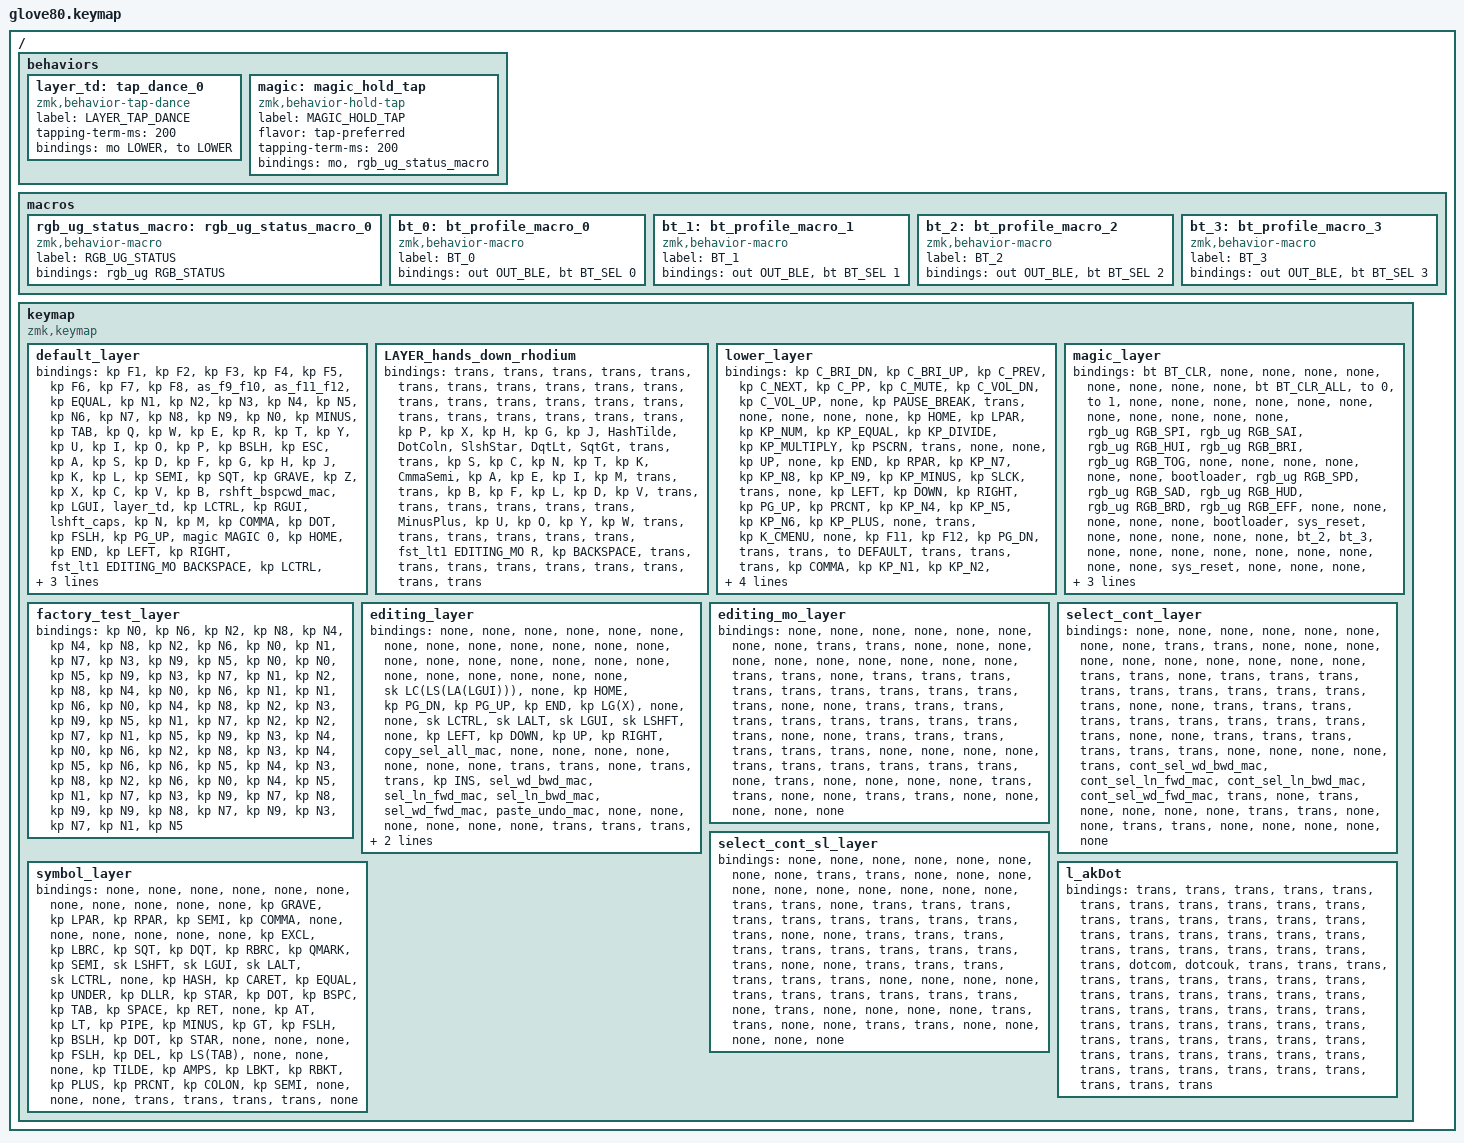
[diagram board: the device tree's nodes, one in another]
/*
 * Copyright (c) 2020 The ZMK Contributors
 *
 * SPDX-License-Identifier: MIT
 */

#include <behaviors.dtsi>
#include <dt-bindings/zmk/keys.h>
#include <dt-bindings/zmk/bt.h>
#include <dt-bindings/zmk/ext_power.h>
#include <dt-bindings/zmk/outputs.h>
#include <dt-bindings/zmk/rgb.h>

// layers
#define DEFAULT 0
#define RHODIUM 1
#define LOWER 2
#define MAGIC 3
#define FACTORY_TEST 4
#define EDITING 5
#define EDITING_MO 6
#define SELECT_CONT 7
#define SELECT_CONT_SL 8
#define SYMBOL 9
#define l_akDot 10

#define BASE_LAYERS DEFAULT
#define layers_hands_down RHODIUM DEFAULT

#include "base.keymap"
#include "keydefinitions.keymap"
#include "handsdown.keymap"

/ {
    behaviors {
        // For the "layer" key, it'd nice to be able to use it as either a shift or a toggle.
        // Configure it as a tap dance, so the first tap (or hold) is a &mo and the second tap is a &to
        layer_td: tap_dance_0 {
            compatible = "zmk,behavior-tap-dance";
            label = "LAYER_TAP_DANCE";
            #binding-cells = <0>;
            tapping-term-ms = <200>;
            bindings = <&mo LOWER>, <&to LOWER>;
        };

        magic: magic_hold_tap {
            compatible = "zmk,behavior-hold-tap";
            label = "MAGIC_HOLD_TAP";
            #binding-cells = <2>;
            flavor = "tap-preferred";
            tapping-term-ms = <200>;
            bindings = <&mo>, <&rgb_ug_status_macro>;
        };
    };

    macros {
        rgb_ug_status_macro: rgb_ug_status_macro_0 {
            label = "RGB_UG_STATUS";
            compatible = "zmk,behavior-macro";
            #binding-cells = <0>;
            bindings
                = <&rgb_ug RGB_STATUS>;
        };

        bt_0: bt_profile_macro_0 {
            label = "BT_0";
            compatible = "zmk,behavior-macro";
            #binding-cells = <0>;
            bindings
                = <&out OUT_BLE>,
                  <&bt BT_SEL 0>;
        };

        bt_1: bt_profile_macro_1 {
            label = "BT_1";
            compatible = "zmk,behavior-macro";
            #binding-cells = <0>;
            bindings
                = <&out OUT_BLE>,
                  <&bt BT_SEL 1>;
        };

        bt_2: bt_profile_macro_2 {
            label = "BT_2";
            compatible = "zmk,behavior-macro";
            #binding-cells = <0>;
            bindings
                = <&out OUT_BLE>,
                  <&bt BT_SEL 2>;
        };

        bt_3: bt_profile_macro_3 {
            label = "BT_3";
            compatible = "zmk,behavior-macro";
            #binding-cells = <0>;
            bindings
                = <&out OUT_BLE>,
                  <&bt BT_SEL 3>;
        };
    };

    keymap {
        compatible = "zmk,keymap";

        default_layer {
            // ---------------------------------------------------------------------------------------------------------------------------------
            // |  F1   |  F2 |  F3 |  F4  |  F5  |                                                               |  F6   |  F7   |  F8  |   F9  |  F10 |
            // |  =    |  1  |  2  |  3   |  4   |  5   |                                                 |  6   |   7   |   8   |  9   |   0   |   -  |
            // |  TAB  |  Q  |  W  |  E   |  R   |  T   |                                                 |  Y   |   U   |   I   |  O   |   P   |   \  |
            // |  ESC  |  A  |  S  |  D   |  F   |  G   |                                                 |  H   |   J   |   K   |  L   |   ;   |   '  |
            // |   `   |  Z  |  X  |  C   |  V   |  B   | LSHFT | LGUI | LOWER | | LCTRL  | RGUI | RSHFT |  N   |   M   |   ,   |  .   |   /   | PGUP |
            // | MAGIC | HOME| END | LEFT | RIGHT|      | BSPC  | LCTRL   | LALT  | | LALT  | RET   | SPACE |      |  UP   | DOWN  |  [   |   ]   | PGDN |

            bindings = <
            &kp F1         &kp F2   &kp F3      &kp F4      &kp F5                                                                                         &kp F6  &kp F7      &kp F8      &as_f9_f10      &as_f11_f12
            &kp EQUAL      &kp N1   &kp N2      &kp N3      &kp N4      &kp N5                                                                     &kp N6  &kp N7  &kp N8      &kp N9      &kp N0      &kp MINUS
            &kp TAB        &kp Q    &kp W       &kp E       &kp R       &kp T                                                                      &kp Y   &kp U   &kp I       &kp O       &kp P       &kp BSLH
            &kp ESC        &kp A    &kp S       &kp D       &kp F       &kp G                                                                      &kp H   &kp J   &kp K       &kp L       &kp SEMI    &kp SQT
            &kp GRAVE      &kp Z    &kp X       &kp C       &kp V       &kp B   &rshft_bspcwd_mac  &kp LGUI   &layer_td  &kp LCTRL  &kp RGUI &lshft_caps   &kp N   &kp M   &kp COMMA   &kp DOT     &kp FSLH    &kp PG_UP
            &magic MAGIC 0 &kp HOME &kp END     &kp LEFT    &kp RIGHT           &fst_lt1 EDITING_MO BACKSPACE    &kp LCTRL     &kp LALT   &kp LALT  &kp RET   &fst_lt SYMBOL SPACE           &kp UP  &kp DOWN    &kp LBKT    &kp RBKT    &kp PG_DN
            >;
        };

        LAYER_hands_down_rhodium {
            bindings = <
    &trans    &trans      &trans      &trans        &trans                                                                                        &trans          &trans          &trans        &trans      &trans
    &trans    &trans      &trans      &trans        &trans          &trans                                                            &trans      &trans          &trans          &trans        &trans      &trans
    &trans    &kp P       &kp X       &kp H         &kp G           &kp J                                                             &HashTilde  &DotColn        &SlshStar       &DqtLt      &SqtGt    &trans
    &trans    &kp S       &kp C       &kp N         &kp T           &kp K                                                             &CmmaSemi   &kp A           &kp E           &kp I         &kp M       &trans
    &trans    &kp B       &kp F       &kp L         &kp D           &kp V     &trans    &trans    &trans  &trans   &trans   &trans    &MinusPlus  &kp U           &kp O           &kp Y         &kp W       &trans
    &trans    &trans      &trans      &trans        &trans                    &fst_lt1 EDITING_MO R     &kp BACKSPACE  &trans  &trans   &trans &trans             &trans          &trans          &trans        &trans      &trans
            >;
        };

        lower_layer {
            bindings = <
            &kp C_BRI_DN      &kp C_BRI_UP        &kp C_PREV      &kp C_NEXT      &kp C_PP                                                                                                           &kp C_MUTE   &kp C_VOL_DN &kp C_VOL_UP  &none           &kp PAUSE_BREAK
            &trans            &none               &none           &none           &none           &kp HOME                                                                              &kp LPAR     &kp KP_NUM   &kp KP_EQUAL &kp KP_DIVIDE &kp KP_MULTIPLY &kp PSCRN
            &trans            &none               &none           &kp UP          &none           &kp END                                                                               &kp RPAR     &kp KP_N7    &kp KP_N8    &kp KP_N9     &kp KP_MINUS    &kp SLCK
            &trans            &none               &kp LEFT        &kp DOWN        &kp RIGHT       &kp PG_UP                                                                             &kp PRCNT    &kp KP_N4    &kp KP_N5    &kp KP_N6     &kp KP_PLUS     &none
            &trans            &kp K_CMENU         &none           &kp F11         &kp F12         &kp PG_DN       &trans      &trans      &to DEFAULT &trans      &trans      &trans    &kp COMMA    &kp KP_N1    &kp KP_N2    &kp KP_N3     &kp KP_ENTER    &trans
            &trans            &kp CAPS            &kp INS         &kp F11         &kp F12                         &trans      &trans      &trans      &trans      &trans      &trans                 &kp KP_N0    &kp KP_N0    &kp KP_DOT    &kp KP_ENTER    &trans
            >;
        };

        magic_layer {
            bindings = <
            &bt BT_CLR        &none               &none           &none           &none                                                                                                           &none      &none      &none      &none      &bt BT_CLR_ALL
            &to 0             &to 1               &none           &none           &none           &none                                                                                &none      &none      &none      &none      &none      &none
            &none             &rgb_ug RGB_SPI     &rgb_ug RGB_SAI &rgb_ug RGB_HUI &rgb_ug RGB_BRI &rgb_ug RGB_TOG                                                                      &none      &none      &none      &none      &none      &none
            &bootloader       &rgb_ug RGB_SPD     &rgb_ug RGB_SAD &rgb_ug RGB_HUD &rgb_ug RGB_BRD &rgb_ug RGB_EFF                                                                      &none      &none      &none      &none      &none      &bootloader
            &sys_reset        &none               &none           &none           &none           &none           &bt_2     &bt_3     &none            &none     &none     &none       &none      &none      &none      &none      &none      &sys_reset
            &none             &none               &none           &none           &none                           &bt_0     &bt_1     &out OUT_USB     &none     &none     &none                  &none      &none      &none      &none      &to FACTORY_TEST
            >;
        };

        factory_test_layer {
            bindings = <
            &kp N0   &kp N6   &kp N2   &kp N8   &kp N4                                                                              &kp N4   &kp N8   &kp N2   &kp N6   &kp N0
            &kp N1   &kp N7   &kp N3   &kp N9   &kp N5   &kp N0                                                            &kp N0   &kp N5   &kp N9   &kp N3   &kp N7   &kp N1
            &kp N2   &kp N8   &kp N4   &kp N0   &kp N6   &kp N1                                                            &kp N1   &kp N6   &kp N0   &kp N4   &kp N8   &kp N2
            &kp N3   &kp N9   &kp N5   &kp N1   &kp N7   &kp N2                                                            &kp N2   &kp N7   &kp N1   &kp N5   &kp N9   &kp N3
            &kp N4   &kp N0   &kp N6   &kp N2   &kp N8   &kp N3   &kp N4   &kp N5   &kp N6      &kp N6   &kp N5   &kp N4   &kp N3   &kp N8   &kp N2   &kp N6   &kp N0   &kp N4
            &kp N5   &kp N1   &kp N7   &kp N3   &kp N9            &kp N7   &kp N8   &kp N9      &kp N9   &kp N8   &kp N7            &kp N9   &kp N3   &kp N7   &kp N1   &kp N5
            >;
        };
        editing_layer {
            bindings = <
  &none      &none     &none     &none                 &none                                                                                      &none            &none            &none              &none   &none
  &none      &none     &none     &none                 &none   &none                                                             &none            &none            &none            &none              &none   &none
  &none      &none     &none     &none  &sk LC(LS(LA(LGUI)))   &none                                                          &kp HOME        &kp PG_DN        &kp PG_UP          &kp END          &kp LG(X)   &none
  &none  &sk LCTRL  &sk LALT  &sk LGUI             &sk LSHFT   &none                                                          &kp LEFT         &kp DOWN           &kp UP        &kp RIGHT  &copy_sel_all_mac   &none
  &none      &none     &none     &none                 &none   &none  &trans  &trans   &none  &trans  &trans  &kp INS  &sel_wd_bwd_mac  &sel_ln_fwd_mac  &sel_ln_bwd_mac  &sel_wd_fwd_mac    &paste_undo_mac   &none
  &none      &none     &none     &none                 &none          &trans  &trans  &trans  &trans  &trans   &trans                             &none            &none            &none              &none   &none
            >;
        };
         editing_mo_layer {
            bindings = <
  &none   &none   &none   &none   &none                                                                   &none   &none   &none  &trans  &trans
  &none   &none   &none   &none   &none   &none                                                   &none   &none   &none   &none  &trans  &trans
  &none  &trans  &trans  &trans  &trans  &trans                                                  &trans  &trans  &trans  &trans  &trans   &none
  &none  &trans  &trans  &trans  &trans  &trans                                                  &trans  &trans  &trans  &trans  &trans   &none
  &none  &trans  &trans  &trans  &trans  &trans  &trans   &none   &none   &none   &none  &trans  &trans  &trans  &trans  &trans  &trans   &none
 &trans   &none   &none   &none   &none          &trans  &trans   &none   &none  &trans  &trans           &none   &none   &none   &none   &none
            >;
        };
        select_cont_layer {
            bindings = <
  &none   &none   &none   &none   &none                                                                                 &none                 &none                 &none                &trans  &trans
  &none   &none   &none   &none   &none   &none                                                   &none                 &none                 &none                 &none                &trans  &trans
  &none  &trans  &trans  &trans  &trans  &trans                                                  &trans                &trans                &trans                &trans                &trans   &none
  &none  &trans  &trans  &trans  &trans  &trans                                                  &trans                &trans                &trans                &trans                &trans   &none
  &none  &trans  &trans  &trans  &trans  &trans  &trans   &none   &none   &none   &none  &trans  &cont_sel_wd_bwd_mac  &cont_sel_ln_fwd_mac  &cont_sel_ln_bwd_mac  &cont_sel_wd_fwd_mac  &trans   &none
 &trans   &none   &none   &none   &none          &trans  &trans   &none   &none  &trans  &trans                         &none                 &none                 &none                 &none   &none
            >;
        };

        select_cont_sl_layer {
            bindings = <
  &none   &none   &none   &none   &none                                                                   &none   &none   &none  &trans  &trans
  &none   &none   &none   &none   &none   &none                                                   &none   &none   &none   &none  &trans  &trans
  &none  &trans  &trans  &trans  &trans  &trans                                                  &trans  &trans  &trans  &trans  &trans   &none
  &none  &trans  &trans  &trans  &trans  &trans                                                  &trans  &trans  &trans  &trans  &trans   &none
  &none  &trans  &trans  &trans  &trans  &trans  &trans   &none   &none   &none   &none  &trans  &trans  &trans  &trans  &trans  &trans   &none
 &trans   &none   &none   &none   &none          &trans  &trans   &none   &none  &trans  &trans           &none   &none   &none   &none   &none
            >;
        };
        symbol_layer {
            bindings = <
     &none      &none      &none      &none     &none                                                                                                        &none                &none                &none                &none   &none
     &none  &kp GRAVE   &kp LPAR   &kp RPAR  &kp SEMI  &kp COMMA                                                                        &none                &none                &none                &none                &none   &none
  &kp EXCL   &kp LBRC    &kp SQT    &kp DQT  &kp RBRC  &kp QMARK                                                                     &kp SEMI             &sk LSHFT             &sk LGUI           &sk LALT             &sk LCTRL   &none
  &kp HASH  &kp CARET  &kp EQUAL  &kp UNDER  &kp DLLR   &kp STAR                                                                      &kp DOT             &kp BSPC              &kp TAB            &kp SPACE              &kp RET   &none
    &kp AT     &kp LT   &kp PIPE  &kp MINUS    &kp GT   &kp FSLH   &kp BSLH    &kp DOT  &kp STAR              &none   &none   &none  &kp FSLH              &kp DEL          &kp LS(TAB)                &none                &none   &none
 &kp TILDE   &kp AMPS   &kp LBKT   &kp RBKT  &kp PLUS             &kp PRCNT  &kp COLON  &kp SEMI              &none   &none   &none                         &trans               &trans               &trans               &trans   &none
            >;
        };

        l_akDot {
            bindings = <
 &trans  &trans  &trans  &trans  &trans                                                                  &trans   &trans    &trans  &trans  &trans
 &trans  &trans  &trans  &trans  &trans  &trans                                                  &trans  &trans   &trans    &trans  &trans  &trans
 &trans  &trans  &trans  &trans  &trans  &trans                                                  &trans  &trans  &dotcom  &dotcouk  &trans  &trans
 &trans  &trans  &trans  &trans  &trans  &trans                                                  &trans  &trans   &trans    &trans  &trans  &trans
 &trans  &trans  &trans  &trans  &trans  &trans  &trans  &trans  &trans  &trans  &trans  &trans  &trans  &trans   &trans    &trans  &trans  &trans
 &trans  &trans  &trans  &trans  &trans          &trans  &trans  &trans  &trans  &trans  &trans          &trans   &trans    &trans  &trans  &trans
            >;
        };
    };
};
